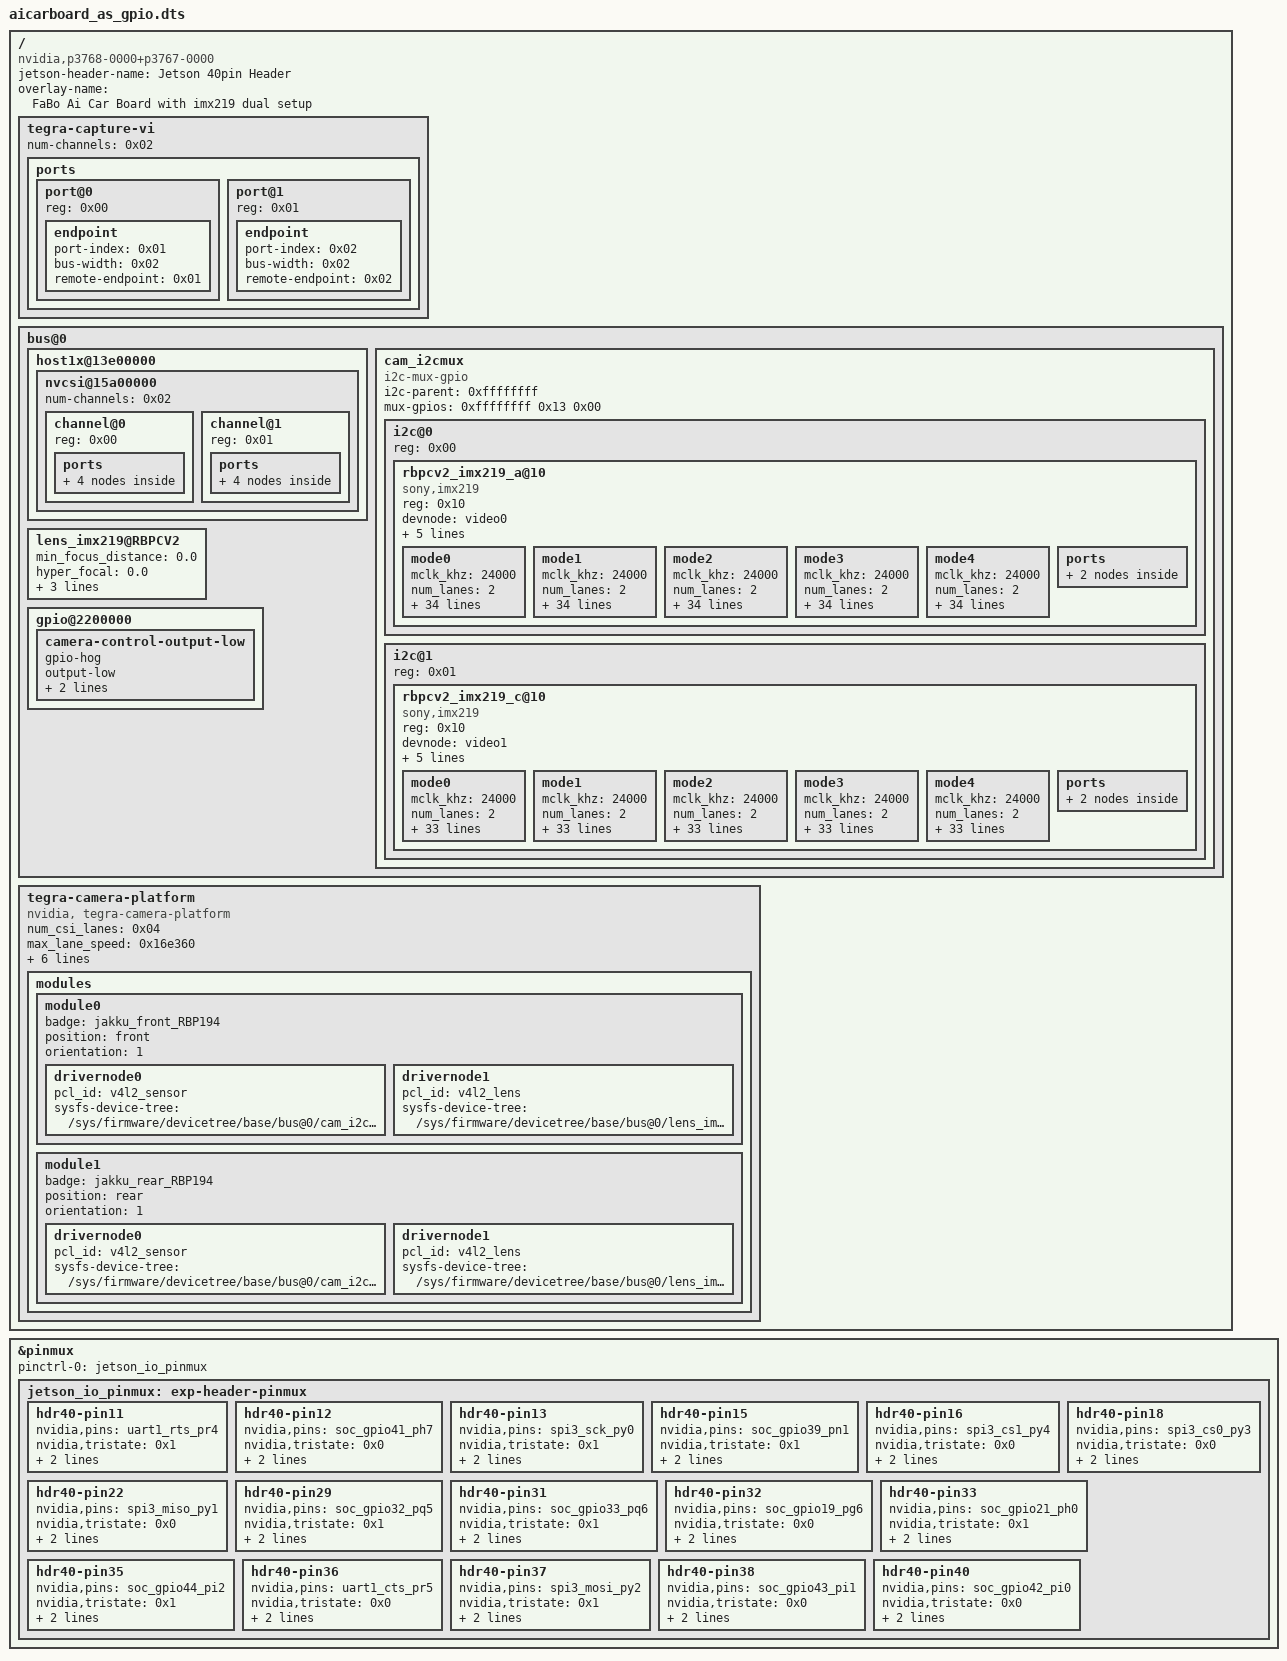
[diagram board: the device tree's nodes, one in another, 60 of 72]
// SPDX-FileCopyrightText: Copyright (c) 2021-2023, NVIDIA CORPORATION & AFFILIATES.  All rights reserved.
// SPDX-License-Identifier: GPL-2.0
/*
 * Copyright (c) 2021-2023, NVIDIA CORPORATION & AFFILIATES.  All rights reserved.
 *
 * This program is free software; you can redistribute it and/or modify it
 * under the terms and conditions of the GNU General Public License,
 * version 2, as published by the Free Software Foundation.
 *
 * This program is distributed in the hope it will be useful, but WITHOUT
 * ANY WARRANTY; without even the implied warranty of MERCHANTABILITY or
 * FITNESS FOR A PARTICULAR PURPOSE.  See the GNU General Public License for
 * more details.
 *
 * You should have received a copy of the GNU General Public License
 * along with this program.  If not, see <http://www.gnu.org/licenses/>.
 */

/*
 * --- MODIFICATION HISTORY ---
 *
 * Modified by: Takeo Nagayama/FaBo Inc.
 * Date:        July 14, 2025
 * Description:
 * - HS-SR04超音波センサー用にGPIOピン設定を追加/調整。
 * - TRIG/ECHOピンの役割に合わせてピンmux設定を最適化。
 * - 具体的な変更内容:
 * - hdr40-pin12,16,18,22,32,36,38,40 (TRIG) を出力として設定し、プルアップ抵抗を追加。
 * - hdr40-pin11,13,15,29,31,33,35,37 (ECHO) を入力として設定。
 * - FaBo AI Car Board（DKFA-05）を対象
 * - CSIカメラはIMX219 Dual設定
 * This modified work is also licensed under the GNU General Public License,
 * version 2, as original work.
 */


/dts-v1/;
/plugin/;

/ {
    jetson-header-name = "Jetson 40pin Header";
    overlay-name = "FaBo Ai Car Board with imx219 dual setup";
    compatible = "nvidia,p3768-0000+p3767-0000\0nvidia,p3768-0000+p3767-0001\0nvidia,p3768-0000+p3767-0003\0nvidia,p3768-0000+p3767-0004\0nvidia,p3768-0000+p3767-0005\0nvidia,p3768-0000+p3767-0000-super\0nvidia,p3768-0000+p3767-0001-super\0nvidia,p3768-0000+p3767-0003-super\0nvidia,p3768-0000+p3767-0004-super\0nvidia,p3768-0000+p3767-0005-super\0nvidia,p3509-0000+p3767-0000\0nvidia,p3509-0000+p3767-0001\0nvidia,p3509-0000+p3767-0003\0nvidia,p3509-0000+p3767-0004\0nvidia,p3509-0000+p3767-0005";


    fragment@0 {
        target = <&pinmux>;

        __overlay__ {
            pinctrl-names = "default";
            pinctrl-0 = <&jetson_io_pinmux>;

            jetson_io_pinmux: exp-header-pinmux {
                hdr40-pin11 {
                        nvidia,pins = "uart1_rts_pr4";
                        nvidia,tristate = <0x1>;
                        nvidia,enable-input = <0x1>;
                        nvidia,pull = <0x0>;	//No-pull
                    };
                 hdr40-pin12 {
                        nvidia,pins = "soc_gpio41_ph7";
                        nvidia,tristate = <0x0>;
                        nvidia,enable-input = <0x0>;
                        nvidia,pull = <0x2>;    //Pull-up
                    };
                hdr40-pin13 {
                        nvidia,pins = "spi3_sck_py0";
                        nvidia,tristate = <0x1>;
                        nvidia,enable-input = <0x1>;
                        nvidia,pull = <0x0>;	//No-pull
                    };
                hdr40-pin15 {
                        nvidia,pins = "soc_gpio39_pn1";
                        nvidia,tristate = <0x1>;
                        nvidia,enable-input = <0x1>;
                        nvidia,pull = <0x0>;	//No-pull
                    };
                hdr40-pin16 {
                        nvidia,pins = "spi3_cs1_py4";
                        nvidia,tristate = <0x0>;
                        nvidia,enable-input = <0x0>;
                        nvidia,pull = <0x2>;    //Pull-up
                    }; 
                hdr40-pin18 {
                        nvidia,pins = "spi3_cs0_py3";
                        nvidia,tristate = <0x0>;
                        nvidia,enable-input = <0x0>;
                        nvidia,pull = <0x2>;    //Pull-up
                    }; 
                hdr40-pin22 {
                        nvidia,pins = "spi3_miso_py1";
                        nvidia,tristate = <0x0>;
                        nvidia,enable-input = <0x0>;
                        nvidia,pull = <0x2>;    //Pull-up
                    }; 
                hdr40-pin29 {
                        nvidia,pins = "soc_gpio32_pq5";
                        nvidia,tristate = <0x1>;
                        nvidia,enable-input = <0x1>;
                        nvidia,pull = <0x0>;	//No-pull
                    }; 
                hdr40-pin31 {
                        nvidia,pins = "soc_gpio33_pq6";
                        nvidia,tristate = <0x1>;
                        nvidia,enable-input = <0x1>;
                        nvidia,pull = <0x0>;	//No-pull
                    }; 
                hdr40-pin32 {
                        nvidia,pins = "soc_gpio19_pg6";
                        nvidia,tristate = <0x0>;
                        nvidia,enable-input = <0x0>;
                        nvidia,pull = <0x2>;    //Pull-up
                    }; 
                hdr40-pin33 {
                        nvidia,pins = "soc_gpio21_ph0";
                        nvidia,tristate = <0x1>;
                        nvidia,enable-input = <0x1>;
                        nvidia,pull = <0x0>;	//No-pull
                    }; 
                hdr40-pin35 {
                        nvidia,pins = "soc_gpio44_pi2";
                        nvidia,tristate = <0x1>;
                        nvidia,enable-input = <0x1>;
                        nvidia,pull = <0x0>;	//No-pull
                    }; 
                hdr40-pin36 {
                        nvidia,pins = "uart1_cts_pr5";
                        nvidia,tristate = <0x0>;
                        nvidia,enable-input = <0x0>;
                        nvidia,pull = <0x2>;    //Pull-up
                    }; 
                hdr40-pin37 {
                        nvidia,pins = "spi3_mosi_py2";
                        nvidia,tristate = <0x1>;
                        nvidia,enable-input = <0x1>;
                        nvidia,pull = <0x0>;	//No-pull
                    }; 
                hdr40-pin38 {
                        nvidia,pins = "soc_gpio43_pi1";
                        nvidia,tristate = <0x0>;
                        nvidia,enable-input = <0x0>;
                        nvidia,pull = <0x2>;    //Pull-up
                    }; 
                hdr40-pin40 {
                        nvidia,pins = "soc_gpio42_pi0";
                        nvidia,tristate = <0x0>;
                        nvidia,enable-input = <0x0>;
                        nvidia,pull = <0x2>;    //Pull-up
                    }; 

             };
        };
    };


fragment-camera@0 {
		target-path = "/";

		__overlay__ {

			tegra-capture-vi {
				num-channels = <0x02>;

				ports {
					#address-cells = <0x01>;
					#size-cells = <0x00>;

					port@0 {
						reg = <0x00>;
						phandle = <0x09>;

						endpoint {
							port-index = <0x01>;
							bus-width = <0x02>;
							remote-endpoint = <0x01>;
							phandle = <0x04>;
						};
					};

					port@1 {
						reg = <0x01>;
						phandle = <0x0a>;

						endpoint {
							port-index = <0x02>;
							bus-width = <0x02>;
							remote-endpoint = <0x02>;
							phandle = <0x06>;
						};
					};
				};
			};

			bus@0 {

				host1x@13e00000 {

					nvcsi@15a00000 {
						num-channels = <0x02>;
						#address-cells = <0x01>;
						#size-cells = <0x00>;

						channel@0 {
							reg = <0x00>;
							phandle = <0x0b>;

							ports {
								#address-cells = <0x01>;
								#size-cells = <0x00>;

								port@0 {
									reg = <0x00>;
									phandle = <0x0c>;

									endpoint@0 {
										port-index = <0x01>;
										bus-width = <0x02>;
										remote-endpoint = <0x03>;
										phandle = <0x07>;
									};
								};

								port@1 {
									reg = <0x01>;
									phandle = <0x0d>;

									endpoint@1 {
										remote-endpoint = <0x04>;
										phandle = <0x01>;
									};
								};
							};
						};

						channel@1 {
							reg = <0x01>;
							phandle = <0x0e>;

							ports {
								#address-cells = <0x01>;
								#size-cells = <0x00>;

								port@0 {
									reg = <0x00>;
									phandle = <0x0f>;

									endpoint@2 {
										port-index = <0x02>;
										bus-width = <0x02>;
										remote-endpoint = <0x05>;
										phandle = <0x08>;
									};
								};

								port@1 {
									reg = <0x01>;
									phandle = <0x10>;

									endpoint@3 {
										remote-endpoint = <0x06>;
										phandle = <0x02>;
									};
								};
							};
						};
					};
				};

				cam_i2cmux {

					i2c@0 {
						phandle = <0x11>;

						rbpcv2_imx219_a@10 {
							compatible = "sony,imx219";
							reg = <0x10>;
							devnode = "video0";
							physical_w = "3.680";
							physical_h = "2.760";
							sensor_model = "imx219";
							use_sensor_mode_id = "true";
							phandle = <0x12>;

							mode0 {
								mclk_khz = "24000";
								num_lanes = "2";
								tegra_sinterface = "serial_b";
								lane_polarity = "6";
								phy_mode = "DPHY";
								discontinuous_clk = "yes";
								dpcm_enable = "false";
								cil_settletime = "0";
								active_w = "3280";
								active_h = "2464";
								mode_type = "bayer";
								pixel_phase = "rggb";
								csi_pixel_bit_depth = "10";
								readout_orientation = "90";
								line_length = "3448";
								inherent_gain = "1";
								mclk_multiplier = "9.33";
								pix_clk_hz = "182400000";
								gain_factor = "16";
								framerate_factor = "1000000";
								exposure_factor = "1000000";
								min_gain_val = "16";
								max_gain_val = "170";
								step_gain_val = "1";
								default_gain = "16";
								min_hdr_ratio = "1";
								max_hdr_ratio = "1";
								min_framerate = "2000000";
								max_framerate = "21000000";
								step_framerate = "1";
								default_framerate = "21000000";
								min_exp_time = "13";
								max_exp_time = "683709";
								step_exp_time = "1";
								default_exp_time = "2495";
								embedded_metadata_height = "2";
							};

							mode1 {
								mclk_khz = "24000";
								num_lanes = "2";
								tegra_sinterface = "serial_b";
								lane_polarity = "6";
								phy_mode = "DPHY";
								discontinuous_clk = "yes";
								dpcm_enable = "false";
								cil_settletime = "0";
								active_w = "3280";
								active_h = "1848";
								mode_type = "bayer";
								pixel_phase = "rggb";
								csi_pixel_bit_depth = "10";
								readout_orientation = "90";
								line_length = "3448";
								inherent_gain = "1";
								mclk_multiplier = "9.33";
								pix_clk_hz = "182400000";
								gain_factor = "16";
								framerate_factor = "1000000";
								exposure_factor = "1000000";
								min_gain_val = "16";
								max_gain_val = "170";
								step_gain_val = "1";
								default_gain = "16";
								min_hdr_ratio = "1";
								max_hdr_ratio = "1";
								min_framerate = "2000000";
								max_framerate = "28000000";
								step_framerate = "1";
								default_framerate = "28000000";
								min_exp_time = "13";
								max_exp_time = "683709";
								step_exp_time = "1";
								default_exp_time = "2495";
								embedded_metadata_height = "2";
							};

							mode2 {
								mclk_khz = "24000";
								num_lanes = "2";
								tegra_sinterface = "serial_b";
								lane_polarity = "6";
								phy_mode = "DPHY";
								discontinuous_clk = "yes";
								dpcm_enable = "false";
								cil_settletime = "0";
								active_w = "1920";
								active_h = "1080";
								mode_type = "bayer";
								pixel_phase = "rggb";
								csi_pixel_bit_depth = "10";
								readout_orientation = "90";
								line_length = "3448";
								inherent_gain = "1";
								mclk_multiplier = "9.33";
								pix_clk_hz = "182400000";
								gain_factor = "16";
								framerate_factor = "1000000";
								exposure_factor = "1000000";
								min_gain_val = "16";
								max_gain_val = "170";
								step_gain_val = "1";
								default_gain = "16";
								min_hdr_ratio = "1";
								max_hdr_ratio = "1";
								min_framerate = "2000000";
								max_framerate = "30000000";
								step_framerate = "1";
								default_framerate = "30000000";
								min_exp_time = "13";
								max_exp_time = "683709";
								step_exp_time = "1";
								default_exp_time = "2495";
								embedded_metadata_height = "2";
							};

							mode3 {
								mclk_khz = "24000";
								num_lanes = "2";
								tegra_sinterface = "serial_b";
								lane_polarity = "6";
								phy_mode = "DPHY";
								discontinuous_clk = "yes";
								dpcm_enable = "false";
								cil_settletime = "0";
								active_w = "1640";
								active_h = "1232";
								mode_type = "bayer";
								pixel_phase = "rggb";
								csi_pixel_bit_depth = "10";
								readout_orientation = "90";
								line_length = "3448";
								inherent_gain = "1";
								mclk_multiplier = "9.33";
								pix_clk_hz = "182400000";
								gain_factor = "16";
								framerate_factor = "1000000";
								exposure_factor = "1000000";
								min_gain_val = "16";
								max_gain_val = "170";
								step_gain_val = "1";
								default_gain = "16";
								min_hdr_ratio = "1";
								max_hdr_ratio = "1";
								min_framerate = "2000000";
								max_framerate = "30000000";
								step_framerate = "1";
								default_framerate = "30000000";
								min_exp_time = "13";
								max_exp_time = "683709";
								step_exp_time = "1";
								default_exp_time = "2495";
								embedded_metadata_height = "2";
							};

							mode4 {
								mclk_khz = "24000";
								num_lanes = "2";
								tegra_sinterface = "serial_b";
								lane_polarity = "6";
								phy_mode = "DPHY";
								discontinuous_clk = "yes";
								dpcm_enable = "false";
								cil_settletime = "0";
								active_w = "1280";
								active_h = "720";
								mode_type = "bayer";
								pixel_phase = "rggb";
								csi_pixel_bit_depth = "10";
								readout_orientation = "90";
								line_length = "3448";
								inherent_gain = "1";
								mclk_multiplier = "9.33";
								pix_clk_hz = "182400000";
								gain_factor = "16";
								framerate_factor = "1000000";
								exposure_factor = "1000000";
								min_gain_val = "16";
								max_gain_val = "170";
								step_gain_val = "1";
								default_gain = "16";
								min_hdr_ratio = "1";
								max_hdr_ratio = "1";
								min_framerate = "2000000";
								max_framerate = "60000000";
								step_framerate = "1";
								default_framerate = "60000000";
								min_exp_time = "13";
								max_exp_time = "683709";
								step_exp_time = "1";
								default_exp_time = "2495";
								embedded_metadata_height = "2";
							};

							ports {
								#address-cells = <0x01>;
								#size-cells = <0x00>;

								port@0 {
									reg = <0x00>;

									endpoint {
										port-index = <0x01>;
										bus-width = <0x02>;
										remote-endpoint = <0x07>;
										phandle = <0x03>;
									};
								};
							};
						};
					};

					i2c@1 {
						phandle = <0x13>;

						rbpcv2_imx219_c@10 {
							compatible = "sony,imx219";
							reg = <0x10>;
							devnode = "video1";
							physical_w = "3.680";
							physical_h = "2.760";
							sensor_model = "imx219";
							use_sensor_mode_id = "true";
							phandle = <0x14>;

							mode0 {
								mclk_khz = "24000";
								num_lanes = "2";
								tegra_sinterface = "serial_c";
								phy_mode = "DPHY";
								discontinuous_clk = "yes";
								dpcm_enable = "false";
								cil_settletime = "0";
								active_w = "3280";
								active_h = "2464";
								mode_type = "bayer";
								pixel_phase = "rggb";
								csi_pixel_bit_depth = "10";
								readout_orientation = "90";
								line_length = "3448";
								inherent_gain = "1";
								mclk_multiplier = "9.33";
								pix_clk_hz = "182400000";
								gain_factor = "16";
								framerate_factor = "1000000";
								exposure_factor = "1000000";
								min_gain_val = "16";
								max_gain_val = "170";
								step_gain_val = "1";
								default_gain = "16";
								min_hdr_ratio = "1";
								max_hdr_ratio = "1";
								min_framerate = "2000000";
								max_framerate = "21000000";
								step_framerate = "1";
								default_framerate = "21000000";
								min_exp_time = "13";
								max_exp_time = "683709";
								step_exp_time = "1";
								default_exp_time = "2495";
								embedded_metadata_height = "2";
							};

							mode1 {
								mclk_khz = "24000";
								num_lanes = "2";
								tegra_sinterface = "serial_c";
								phy_mode = "DPHY";
								discontinuous_clk = "yes";
								dpcm_enable = "false";
								cil_settletime = "0";
								active_w = "3280";
								active_h = "1848";
								mode_type = "bayer";
								pixel_phase = "rggb";
								csi_pixel_bit_depth = "10";
								readout_orientation = "90";
								line_length = "3448";
								inherent_gain = "1";
								mclk_multiplier = "9.33";
								pix_clk_hz = "182400000";
								gain_factor = "16";
								framerate_factor = "1000000";
								exposure_factor = "1000000";
								min_gain_val = "16";
								max_gain_val = "170";
								step_gain_val = "1";
								default_gain = "16";
								min_hdr_ratio = "1";
								max_hdr_ratio = "1";
								min_framerate = "2000000";
								max_framerate = "28000000";
								step_framerate = "1";
								default_framerate = "28000000";
								min_exp_time = "13";
								max_exp_time = "683709";
								step_exp_time = "1";
								default_exp_time = "2495";
								embedded_metadata_height = "2";
							};

							mode2 {
								mclk_khz = "24000";
								num_lanes = "2";
								tegra_sinterface = "serial_c";
								phy_mode = "DPHY";
								discontinuous_clk = "yes";
								dpcm_enable = "false";
								cil_settletime = "0";
								active_w = "1920";
								active_h = "1080";
								mode_type = "bayer";
								pixel_phase = "rggb";
								csi_pixel_bit_depth = "10";
								readout_orientation = "90";
								line_length = "3448";
								inherent_gain = "1";
								mclk_multiplier = "9.33";
								pix_clk_hz = "182400000";
								gain_factor = "16";
								framerate_factor = "1000000";
								exposure_factor = "1000000";
								min_gain_val = "16";
								max_gain_val = "170";
								step_gain_val = "1";
								default_gain = "16";
								min_hdr_ratio = "1";
								max_hdr_ratio = "1";
								min_framerate = "2000000";
								max_framerate = "30000000";
								step_framerate = "1";
								default_framerate = "30000000";
								min_exp_time = "13";
								max_exp_time = "683709";
								step_exp_time = "1";
								default_exp_time = "2495";
								embedded_metadata_height = "2";
							};

							mode3 {
								mclk_khz = "24000";
								num_lanes = "2";
								tegra_sinterface = "serial_c";
								phy_mode = "DPHY";
								discontinuous_clk = "yes";
								dpcm_enable = "false";
								cil_settletime = "0";
								active_w = "1640";
								active_h = "1232";
								mode_type = "bayer";
								pixel_phase = "rggb";
								csi_pixel_bit_depth = "10";
								readout_orientation = "90";
								line_length = "3448";
								inherent_gain = "1";
								mclk_multiplier = "9.33";
								pix_clk_hz = "182400000";
								gain_factor = "16";
								framerate_factor = "1000000";
								exposure_factor = "1000000";
								min_gain_val = "16";
								max_gain_val = "170";
								step_gain_val = "1";
								default_gain = "16";
								min_hdr_ratio = "1";
								max_hdr_ratio = "1";
								min_framerate = "2000000";
								max_framerate = "30000000";
								step_framerate = "1";
								default_framerate = "30000000";
								min_exp_time = "13";
								max_exp_time = "683709";
								step_exp_time = "1";
								default_exp_time = "2495";
								embedded_metadata_height = "2";
							};

							mode4 {
								mclk_khz = "24000";
								num_lanes = "2";
								tegra_sinterface = "serial_c";
								phy_mode = "DPHY";
								discontinuous_clk = "yes";
								dpcm_enable = "false";
								cil_settletime = "0";
								active_w = "1280";
								active_h = "720";
								mode_type = "bayer";
								pixel_phase = "rggb";
								csi_pixel_bit_depth = "10";
								readout_orientation = "90";
								line_length = "3448";
								inherent_gain = "1";
								mclk_multiplier = "9.33";
								pix_clk_hz = "182400000";
								gain_factor = "16";
								framerate_factor = "1000000";
								exposure_factor = "1000000";
								min_gain_val = "16";
								max_gain_val = "170";
								step_gain_val = "1";
								default_gain = "16";
								min_hdr_ratio = "1";
								max_hdr_ratio = "1";
								min_framerate = "2000000";
								max_framerate = "60000000";
								step_framerate = "1";
								default_framerate = "60000000";
								min_exp_time = "13";
								max_exp_time = "683709";
								step_exp_time = "1";
								default_exp_time = "2495";
								embedded_metadata_height = "2";
							};

							ports {
								#address-cells = <0x01>;
								#size-cells = <0x00>;

								port@0 {
									reg = <0x00>;

									endpoint {
										port-index = <0x02>;
										bus-width = <0x02>;
										remote-endpoint = <0x08>;
										phandle = <0x05>;
									};
								};
							};
						};
					};
				};

				lens_imx219@RBPCV2 {
					min_focus_distance = "0.0";
					hyper_focal = "0.0";
					focal_length = "3.04";
					f_number = "2.0";
					aperture = "0.0";
				};
			};

			tegra-camera-platform {
				compatible = "nvidia, tegra-camera-platform";
				num_csi_lanes = <0x04>;
				max_lane_speed = <0x16e360>;
				min_bits_per_pixel = <0x0a>;
				vi_peak_byte_per_pixel = <0x02>;
				vi_bw_margin_pct = <0x19>;
				max_pixel_rate = <0x3a980>;
				isp_peak_byte_per_pixel = <0x05>;
				isp_bw_margin_pct = <0x19>;
				phandle = <0x15>;

				modules {

					module0 {
						badge = "jakku_front_RBP194";
						position = "front";
						orientation = "1";
						phandle = <0x16>;

						drivernode0 {
							pcl_id = "v4l2_sensor";
							sysfs-device-tree = "/sys/firmware/devicetree/base/bus@0/cam_i2cmux/i2c@0/rbpcv2_imx219_a@10";
							phandle = <0x17>;
						};

						drivernode1 {
							pcl_id = "v4l2_lens";
							sysfs-device-tree = "/sys/firmware/devicetree/base/bus@0/lens_imx219@RBPCV2";
							phandle = <0x18>;
						};
					};

					module1 {
						badge = "jakku_rear_RBP194";
						position = "rear";
						orientation = "1";
						phandle = <0x19>;

						drivernode0 {
							pcl_id = "v4l2_sensor";
							sysfs-device-tree = "/sys/firmware/devicetree/base/bus@0/cam_i2cmux/i2c@1/rbpcv2_imx219_c@10";
							phandle = <0x1a>;
						};

						drivernode1 {
							pcl_id = "v4l2_lens";
							sysfs-device-tree = "/sys/firmware/devicetree/base/bus@0/lens_imx219@RBPCV2/";
							phandle = <0x1b>;
						};
					};
				};
			};
		};
	};

	fragment-camera-imx219@0 {
		target-path = "/";

		__overlay__ {

			bus@0 {

				cam_i2cmux {
					status = "okay";
					compatible = "i2c-mux-gpio";
					#address-cells = <0x01>;
					#size-cells = <0x00>;
					i2c-parent = <0xffffffff>;
					mux-gpios = <0xffffffff 0x13 0x00>;

					i2c@0 {
						status = "okay";
						reg = <0x00>;
						#address-cells = <0x01>;
						#size-cells = <0x00>;

						rbpcv2_imx219_a@10 {
							reset-gpios = <0xffffffff 0x3e 0x00>;
						};
					};

					i2c@1 {
						status = "okay";
						reg = <0x01>;
						#address-cells = <0x01>;
						#size-cells = <0x00>;

						rbpcv2_imx219_c@10 {
							reset-gpios = <0xffffffff 0xa0 0x00>;
						};
					};
				};

				gpio@2200000 {

					camera-control-output-low {
						gpio-hog;
						output-low;
						gpios = <0x3b 0x00>;
						label = "cam0-rst";
					};
				};
			};
		};
	};

	__symbols__ {
		vi_port0 = "/fragment-camera@0/__overlay__/tegra-capture-vi/ports/port@0";
		rbpcv2_imx219_vi_in0 = "/fragment-camera@0/__overlay__/tegra-capture-vi/ports/port@0/endpoint";
		vi_port1 = "/fragment-camera@0/__overlay__/tegra-capture-vi/ports/port@1";
		rbpcv2_imx219_vi_in1 = "/fragment-camera@0/__overlay__/tegra-capture-vi/ports/port@1/endpoint";
		csi_chan0 = "/fragment-camera@0/__overlay__/bus@0/host1x@13e00000/nvcsi@15a00000/channel@0";
		csi_chan0_port0 = "/fragment-camera@0/__overlay__/bus@0/host1x@13e00000/nvcsi@15a00000/channel@0/ports/port@0";
		rbpcv2_imx219_csi_in0 = "/fragment-camera@0/__overlay__/bus@0/host1x@13e00000/nvcsi@15a00000/channel@0/ports/port@0/endpoint@0";
		csi_chan0_port1 = "/fragment-camera@0/__overlay__/bus@0/host1x@13e00000/nvcsi@15a00000/channel@0/ports/port@1";
		rbpcv2_imx219_csi_out0 = "/fragment-camera@0/__overlay__/bus@0/host1x@13e00000/nvcsi@15a00000/channel@0/ports/port@1/endpoint@1";
		csi_chan1 = "/fragment-camera@0/__overlay__/bus@0/host1x@13e00000/nvcsi@15a00000/channel@1";
		csi_chan1_port0 = "/fragment-camera@0/__overlay__/bus@0/host1x@13e00000/nvcsi@15a00000/channel@1/ports/port@0";
		rbpcv2_imx219_csi_in1 = "/fragment-camera@0/__overlay__/bus@0/host1x@13e00000/nvcsi@15a00000/channel@1/ports/port@0/endpoint@2";
		csi_chan1_port1 = "/fragment-camera@0/__overlay__/bus@0/host1x@13e00000/nvcsi@15a00000/channel@1/ports/port@1";
		rbpcv2_imx219_csi_out1 = "/fragment-camera@0/__overlay__/bus@0/host1x@13e00000/nvcsi@15a00000/channel@1/ports/port@1/endpoint@3";
		i2c_0 = "/fragment-camera@0/__overlay__/bus@0/cam_i2cmux/i2c@0";
		imx219_cam0 = "/fragment-camera@0/__overlay__/bus@0/cam_i2cmux/i2c@0/rbpcv2_imx219_a@10";
		rbpcv2_imx219_out0 = "/fragment-camera@0/__overlay__/bus@0/cam_i2cmux/i2c@0/rbpcv2_imx219_a@10/ports/port@0/endpoint";
		i2c_1 = "/fragment-camera@0/__overlay__/bus@0/cam_i2cmux/i2c@1";
		imx219_cam1 = "/fragment-camera@0/__overlay__/bus@0/cam_i2cmux/i2c@1/rbpcv2_imx219_c@10";
		rbpcv2_imx219_out1 = "/fragment-camera@0/__overlay__/bus@0/cam_i2cmux/i2c@1/rbpcv2_imx219_c@10/ports/port@0/endpoint";
		tcp = "/fragment-camera@0/__overlay__/tegra-camera-platform";
		cam_module0 = "/fragment-camera@0/__overlay__/tegra-camera-platform/modules/module0";
		cam_module0_drivernode0 = "/fragment-camera@0/__overlay__/tegra-camera-platform/modules/module0/drivernode0";
		cam_module0_drivernode1 = "/fragment-camera@0/__overlay__/tegra-camera-platform/modules/module0/drivernode1";
		cam_module1 = "/fragment-camera@0/__overlay__/tegra-camera-platform/modules/module1";
		cam_module1_drivernode0 = "/fragment-camera@0/__overlay__/tegra-camera-platform/modules/module1/drivernode0";
		cam_module1_drivernode1 = "/fragment-camera@0/__overlay__/tegra-camera-platform/modules/module1/drivernode1";
	};

	__fixups__ {
		cam_i2c = "/fragment-camera-imx219@0/__overlay__/bus@0/cam_i2cmux:i2c-parent:0";
		gpio_aon = "/fragment-camera-imx219@0/__overlay__/bus@0/cam_i2cmux:mux-gpios:0";
		gpio = "/fragment-camera-imx219@0/__overlay__/bus@0/cam_i2cmux/i2c@0/rbpcv2_imx219_a@10:reset-gpios:0\0/fragment-camera-imx219@0/__overlay__/bus@0/cam_i2cmux/i2c@1/rbpcv2_imx219_c@10:reset-gpios:0";
	};

	__local_fixups__ {

		fragment-camera@0 {

			__overlay__ {

				tegra-capture-vi {

					ports {

						port@0 {

							endpoint {
								remote-endpoint = <0x00>;
							};
						};

						port@1 {

							endpoint {
								remote-endpoint = <0x00>;
							};
						};
					};
				};

				bus@0 {

					host1x@13e00000 {

						nvcsi@15a00000 {

							channel@0 {

								ports {

									port@0 {

										endpoint@0 {
											remote-endpoint = <0x00>;
										};
									};

									port@1 {

										endpoint@1 {
											remote-endpoint = <0x00>;
										};
									};
								};
							};

							channel@1 {

								ports {

									port@0 {

										endpoint@2 {
											remote-endpoint = <0x00>;
										};
									};

									port@1 {

										endpoint@3 {
											remote-endpoint = <0x00>;
										};
									};
								};
							};
						};
					};

					cam_i2cmux {

						i2c@0 {

							rbpcv2_imx219_a@10 {

								ports {

									port@0 {

										endpoint {
											remote-endpoint = <0x00>;
										};
									};
								};
							};
						};

						i2c@1 {

							rbpcv2_imx219_c@10 {

								ports {

									port@0 {

										endpoint {
											remote-endpoint = <0x00>;
										};
									};
								};
							};
						};
					};
				};
			};
		};
	};
};
